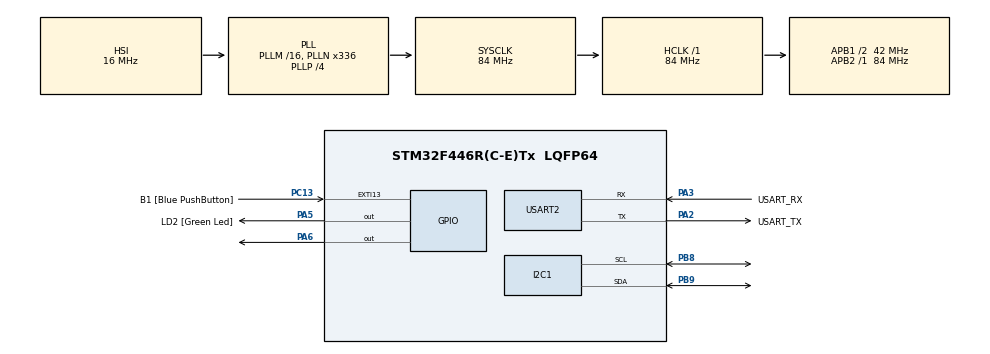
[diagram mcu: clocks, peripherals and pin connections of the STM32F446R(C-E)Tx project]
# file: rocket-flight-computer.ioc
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Mcu.Family=STM32F4
Mcu.Name=STM32F446R(C-E)Tx
Mcu.Package=LQFP64
NVIC.PriorityGroup=NVIC_PRIORITYGROUP_0
PA13.GPIO_Label=TMS
PA13.Mode=Serial_Wire
PA13.Signal=SYS_JTMS-SWDIO
PA14.GPIO_Label=TCK
PA14.Mode=Serial_Wire
PA14.Signal=SYS_JTCK-SWCLK
PA2.GPIO_Label=USART_TX
PA2.Mode=Asynchronous
PA2.Signal=USART2_TX
PA3.GPIO_Label=USART_RX
PA3.Mode=Asynchronous
PA3.Signal=USART2_RX
PA5.GPIO_Label=LD2 [Green Led]
PA5.Signal=GPIO_Output
PA6.Signal=GPIO_Output
PB3.GPIO_Label=SWO
PB3.Signal=SYS_JTDO-SWO
PB8.Mode=I2C
PB8.Signal=I2C1_SCL
PB9.Mode=I2C
PB9.Signal=I2C1_SDA
PC13.GPIO_Label=B1 [Blue PushButton]
PC13.GPIO_ModeDefaultEXTI=GPIO_MODE_IT_FALLING
PC13.Signal=GPXTI13
PC14-OSC32_IN.Mode=LSE-External-Oscillator
PC14-OSC32_IN.Signal=RCC_OSC32_IN
PC15-OSC32_OUT.Mode=LSE-External-Oscillator
PC15-OSC32_OUT.Signal=RCC_OSC32_OUT
PH0-OSC_IN.Mode=HSE-External-Oscillator
PH0-OSC_IN.Signal=RCC_OSC_IN
PH1-OSC_OUT.Mode=HSE-External-Oscillator
PH1-OSC_OUT.Signal=RCC_OSC_OUT
ProjectManager.HeapSize=0x200
ProjectManager.StackSize=0x400
ProjectManager.TargetToolchain=STM32CubeIDE
RCC.48MHZClocksFreq_Value=84000000
RCC.AHBFreq_Value=84000000
RCC.APB1CLKDivider=RCC_HCLK_DIV2
RCC.APB1Freq_Value=42000000
RCC.APB1TimFreq_Value=84000000
RCC.APB2Freq_Value=84000000
RCC.APB2TimFreq_Value=84000000
RCC.CortexFreq_Value=84000000
RCC.FLatency-AdvancedSettings=FLASH_LATENCY_2
RCC.HCLKFreq_Value=84000000
RCC.HSE_VALUE=8000000
RCC.HSI_VALUE=16000000
RCC.PLLN=336
RCC.PLLP=RCC_PLLP_DIV4
RCC.SYSCLKFreq_VALUE=84000000
RCC.SYSCLKSource=RCC_SYSCLKSOURCE_PLLCLK
RCC.USBFreq_Value=168000000
RCC.VCOOutputFreq_Value=336000000
USART2.VirtualMode=VM_ASYNC
board=NUCLEO-F446RE

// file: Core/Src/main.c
/* USER CODE BEGIN Header */
/**
 ******************************************************************************
 * @file           : main.c
 * @brief          : Main program body
 ******************************************************************************
 * @attention
 *
 * Copyright (c) 2026 STMicroelectronics.
 * All rights reserved.
 *
 * This software is licensed under terms that can be found in the LICENSE file
 * in the root directory of this software component.
 * If no LICENSE file comes with this software, it is provided AS-IS.
 *
 ******************************************************************************
 */
/* USER CODE END Header */
#include <i2c_recover.h>
#include "main.h"
#include <stdio.h>
#include <math.h>
#include "mpu6050.h"
#include "sensor_fusion.h"

I2C_HandleTypeDef hi2c1;

UART_HandleTypeDef huart2;

int __io_putchar(int ch)
{
    HAL_UART_Transmit(&huart2, (uint8_t *)&ch, 1, HAL_MAX_DELAY);
    return ch;
}

void SystemClock_Config(void);
static void MX_GPIO_Init(void);
static void MX_USART2_UART_Init(void);
static void MX_I2C1_Init(void);
/* USER CODE BEGIN PFP */
static HAL_StatusTypeDef IMU_Recover(HAL_HandleTypeDef *imu);
/* USER CODE END PFP */

int main(void) {

	/* MCU Configuration--------------------------------------------------------*/

	/* Reset of all peripherals, Initializes the Flash interface and the Systick. */
	HAL_Init();

	/* Configure the system clock */
	SystemClock_Config();

	/* Initialize all configured peripherals */
	MX_GPIO_Init();
	MX_USART2_UART_Init();
	MX_I2C1_Init();

	HAL_Delay(100); // Give the MPU6050 time to power up and become ready before communicating with it.

	MPU6050_Data imu;
	Attitude attitude;
	uint32_t fusion_dt_ms; // delay time since last mpu6090 values update and fusion
	uint32_t telemetry_dt_ms; // time interval for telemetry
	uint32_t current_time;

	HAL_StatusTypeDef status;
	status = MPU6050_Init(&hi2c1);
	while(status != HAL_OK) {
		I2C_BusClear(&hi2c1);
		MX_I2C1_Init();
		printf("MPU initialization failed, retrying\r\n");
		status = MPU6050_Init(&hi2c1);
	}

	status = MPU6050_CalibrateGyro();
	while(status != HAL_OK) {
		printf("MPU calibration failed, retrying after 300ms\r\n");
		HAL_Delay(300);
		status = MPU6050_CalibrateGyro();
	}

	// first read for the sensor
	status = MPU6050_Read(&imu);
	while(status != HAL_OK) {
		printf("MPU read failed, retrying");
		status = MPU6050_Read(&imu);
	}

	sensorFusion_Init(&imu, &attitude);

	uint32_t previousFusionTime = 0;
	uint32_t previousTelemetryTime = 0;

	//main loop
	while (1) {
		current_time = HAL_GetTick();
		fusion_dt_ms = current_time - previousFusionTime;
		telemetry_dt_ms = current_time - previousTelemetryTime;

		if(fusion_dt_ms >= FUSION_PERIOD) {
			status = MPU6050_Read(&imu);

			while(status != HAL_OK) {
				if(!IMU_Recover(&hi2c1)) {
					continue;
				}
				status = MPU6050_Read(&imu);
			}

			sensorFusion_Update(&imu, fusion_dt_ms, &attitude);
			previousFusionTime += FUSION_PERIOD;
		}

		if(telemetry_dt_ms >= TELEMETRY_PERIOD) {
			printf("T: %lu\r\n\r\n"
				"Roll: %.2f\r\n"
				"Pitch: %.2f\r\n",
			current_time, attitude.roll_deg, attitude.pitch_deg);

			previousTelemetryTime += TELEMETRY_PERIOD;
		}
	}
	/* USER CODE END 3 */
}

void SystemClock_Config(void) {
	RCC_OscInitTypeDef RCC_OscInitStruct = { 0 };
	RCC_ClkInitTypeDef RCC_ClkInitStruct = { 0 };

	/** Configure the main internal regulator output voltage
	 */
	__HAL_RCC_PWR_CLK_ENABLE();
	__HAL_PWR_VOLTAGESCALING_CONFIG(PWR_REGULATOR_VOLTAGE_SCALE3);

	/** Initializes the RCC Oscillators according to the specified parameters
	 * in the RCC_OscInitTypeDef structure.
	 */
	RCC_OscInitStruct.OscillatorType = RCC_OSCILLATORTYPE_HSI;
	RCC_OscInitStruct.HSIState = RCC_HSI_ON;
	RCC_OscInitStruct.HSICalibrationValue = RCC_HSICALIBRATION_DEFAULT;
	RCC_OscInitStruct.PLL.PLLState = RCC_PLL_ON;
	RCC_OscInitStruct.PLL.PLLSource = RCC_PLLSOURCE_HSI;
	RCC_OscInitStruct.PLL.PLLM = 16;
	RCC_OscInitStruct.PLL.PLLN = 336;
	RCC_OscInitStruct.PLL.PLLP = RCC_PLLP_DIV4;
	RCC_OscInitStruct.PLL.PLLQ = 2;
	RCC_OscInitStruct.PLL.PLLR = 2;
	if (HAL_RCC_OscConfig(&RCC_OscInitStruct) != HAL_OK) {
		Error_Handler();
	}

	/** Initializes the CPU, AHB and APB buses clocks
	 */
	RCC_ClkInitStruct.ClockType = RCC_CLOCKTYPE_HCLK | RCC_CLOCKTYPE_SYSCLK
			| RCC_CLOCKTYPE_PCLK1 | RCC_CLOCKTYPE_PCLK2;
	RCC_ClkInitStruct.SYSCLKSource = RCC_SYSCLKSOURCE_PLLCLK;
	RCC_ClkInitStruct.AHBCLKDivider = RCC_SYSCLK_DIV1;
	RCC_ClkInitStruct.APB1CLKDivider = RCC_HCLK_DIV2;
	RCC_ClkInitStruct.APB2CLKDivider = RCC_HCLK_DIV1;

	if (HAL_RCC_ClockConfig(&RCC_ClkInitStruct, FLASH_LATENCY_2) != HAL_OK) {
		Error_Handler();
	}
}

static void MX_I2C1_Init(void) {

	hi2c1.Instance = I2C1;
	hi2c1.Init.ClockSpeed = 100000;
	hi2c1.Init.DutyCycle = I2C_DUTYCYCLE_2;
	hi2c1.Init.OwnAddress1 = 0;
	hi2c1.Init.AddressingMode = I2C_ADDRESSINGMODE_7BIT;
	hi2c1.Init.DualAddressMode = I2C_DUALADDRESS_DISABLE;
	hi2c1.Init.OwnAddress2 = 0;
	hi2c1.Init.GeneralCallMode = I2C_GENERALCALL_DISABLE;
	hi2c1.Init.NoStretchMode = I2C_NOSTRETCH_DISABLE;
	if (HAL_I2C_Init(&hi2c1) != HAL_OK) {
		Error_Handler();
	}

}

static void MX_USART2_UART_Init(void) {

	huart2.Instance = USART2;
	huart2.Init.BaudRate = 115200;
	huart2.Init.WordLength = UART_WORDLENGTH_8B;
	huart2.Init.StopBits = UART_STOPBITS_1;
	huart2.Init.Parity = UART_PARITY_NONE;
	huart2.Init.Mode = UART_MODE_TX_RX;
	huart2.Init.HwFlowCtl = UART_HWCONTROL_NONE;
	huart2.Init.OverSampling = UART_OVERSAMPLING_16;
	if (HAL_UART_Init(&huart2) != HAL_OK) {
		Error_Handler();
	}

}

static void MX_GPIO_Init(void) {
	GPIO_InitTypeDef GPIO_InitStruct = { 0 };

	/* GPIO Ports Clock Enable */
	__HAL_RCC_GPIOC_CLK_ENABLE();
	__HAL_RCC_GPIOH_CLK_ENABLE();
	__HAL_RCC_GPIOA_CLK_ENABLE();
	__HAL_RCC_GPIOB_CLK_ENABLE();

	/*Configure GPIO pin Output Level */
	HAL_GPIO_WritePin(GPIOA, LD2_Pin | GPIO_PIN_6, GPIO_PIN_RESET);

	/*Configure GPIO pin : B1_Pin */
	GPIO_InitStruct.Pin = B1_Pin;
	GPIO_InitStruct.Mode = GPIO_MODE_IT_FALLING;
	GPIO_InitStruct.Pull = GPIO_NOPULL;
	HAL_GPIO_Init(B1_GPIO_Port, &GPIO_InitStruct);

	/*Configure GPIO pins : LD2_Pin PA6 */
	GPIO_InitStruct.Pin = LD2_Pin | GPIO_PIN_6;
	GPIO_InitStruct.Mode = GPIO_MODE_OUTPUT_PP;
	GPIO_InitStruct.Pull = GPIO_NOPULL;
	GPIO_InitStruct.Speed = GPIO_SPEED_FREQ_LOW;
	HAL_GPIO_Init(GPIOA, &GPIO_InitStruct);

}

/* USER CODE BEGIN 4 */
/**
 * @brief This function is executed in cas of error occurence in communitcation with the MPU6050 module
 * @param hi2c1 I2C Handler
 * @retval Status of the communication with the MPU module(if the i2c bus is clear,
 * 			if the MPU responds when trying to communicate with it, if the correct module is connected)
 */
static HAL_StatusTypeDef IMU_Recover(I2c_HandleTypeDef *hi2c1) {
	HAL_StatusTypeDef status;

	status = I2C_BusClear(hi2c1);
	if(status != HAL_OK) {
		return HAL_ERROR;
	}

	status = MPU6050_Check();
	if(status != HAL_OK) {
		return HAL_ERROR;
	}

	status = MPU6050_ReadWhoAmI();
	if(status != HAL_OK) {
		return HAL_ERROR;
	}

	return HAL_OK;
}
/* USER CODE END 4 */

void Error_Handler(void) {
	__disable_irq();
	while (1) {
	}
}
